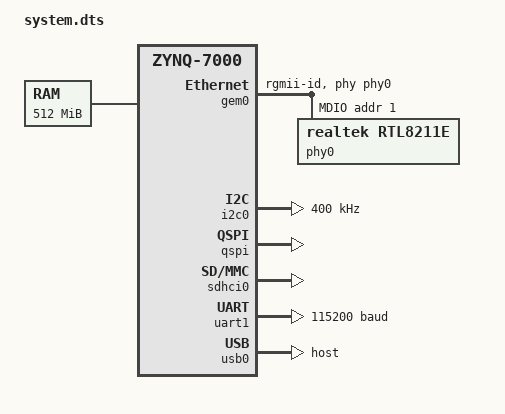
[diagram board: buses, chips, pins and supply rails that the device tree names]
/*
 * CAUTION: This file is automatically generated by Xilinx.
 * Version:  
 * Today is: Fri Jun 17 21:14:59 2016
*/


/dts-v1/;
/include/ "zynq-7000.dtsi"
/include/ "pl.dtsi"
/ {
	cpus {
		cpu@0 {
			operating-points = <650000 1000000 325000 1000000>;
		};
	};
	chosen {
		bootargs = "console=ttyPS0,115200 rootfstype=ext4 root=/dev/mmcblk0p2 rootwait rw";
	};
	aliases {
		ethernet0 = &gem0;
		serial0 = &uart1;
		spi0 = &qspi;
	};
	memory {
		device_type = "memory";
		reg = <0x0 0x20000000>;
	};
};
&adc
{	xlnx,channels 
	{
		#address-cells = <0x1>;
		#size-cells = <0x0>;
		channel@6 
		{
			reg = <7>;
		};
		channel@7
		{
			reg = <8>;
		};
		channel@14 
		{
			reg = <15>;
		};
		channel@15
		{
			reg = <16>;
		};
	};
};
&gem0 
{
	local-mac-address = [00 0a 35 00 00 00];
	phy-handle = <&phy0>;
	phy-mode = "rgmii-id";
	status = "okay";
	xlnx,ptp-enet-clock = <0x6750918>;
	ps7_ethernet_0_mdio: mdio 
	{
		#address-cells = <1>;
		#size-cells = <0>;
	  	phy0: phy@0 
		{
			compatible = "realtek,RTL8211E";
			device_type = "ethernet-phy";
	   		reg = <1>;
		} ;
	};
};
&gpio0 {
	emio-gpio-wih = <64>;
	gpio-mask-high = <0x0>;
	gpio-mask-low = <0x5600>;
};
&i2c0 {
	clock-frequency = <400000>;
	status = "okay";
};
&intc {
	num_cpus = <2>;
	num_interrupts = <96>;
};
&qspi {
	is-dual = <0>;
	num-cs = <1>;
	status = "okay";
};
&sdhci0 {
	status = "okay";
	xlnx,has-cd = <0x1>;
	xlnx,has-power = <0x0>;
	xlnx,has-wp = <0x1>;
};
&uart1 {
	current-speed = <115200>;
	device_type = "serial";
	port-number = <0>;
	status = "okay";
};
&usb0 {
	dr_mode = "host";
	phy_type = "ulpi";
	status = "okay";
};
&clkc {
	fclk-enable = <0x1>;
	ps-clk-frequency = <50000000>;
};
